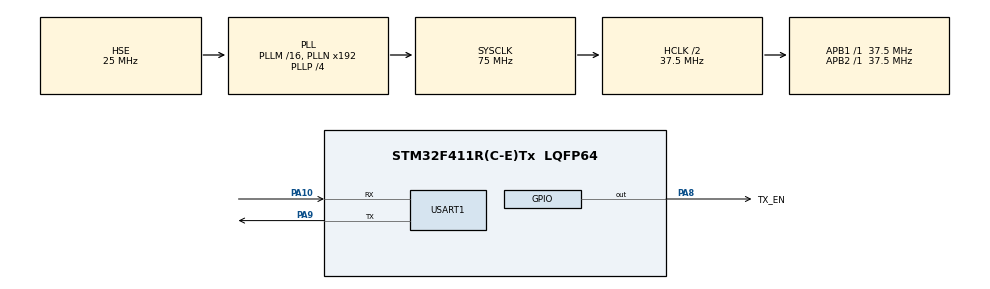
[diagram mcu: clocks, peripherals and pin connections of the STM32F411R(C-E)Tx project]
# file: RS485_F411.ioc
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Mcu.Family=STM32F4
Mcu.Name=STM32F411R(C-E)Tx
Mcu.Package=LQFP64
NVIC.PriorityGroup=NVIC_PRIORITYGROUP_4
NVIC.USART1_IRQn=true\:0\:0\:false\:false\:true\:true\:true\:true
PA10.Mode=Asynchronous
PA10.Signal=USART1_RX
PA13.Mode=Serial_Wire
PA13.Signal=SYS_JTMS-SWDIO
PA14.Mode=Serial_Wire
PA14.Signal=SYS_JTCK-SWCLK
PA8.GPIO_Label=TX_EN
PA8.Signal=GPIO_Output
PA9.Mode=Asynchronous
PA9.Signal=USART1_TX
PH0\ -\ OSC_IN.Mode=HSE-External-Oscillator
PH0\ -\ OSC_IN.Signal=RCC_OSC_IN
PH1\ -\ OSC_OUT.Mode=HSE-External-Oscillator
PH1\ -\ OSC_OUT.Signal=RCC_OSC_OUT
ProjectManager.HeapSize=0x200
ProjectManager.StackSize=0x400
ProjectManager.TargetToolchain=STM32CubeIDE
RCC.48MHZClocksFreq_Value=75000000
RCC.AHBCLKDivider=RCC_SYSCLK_DIV2
RCC.AHBFreq_Value=37500000
RCC.APB1Freq_Value=37500000
RCC.APB1TimFreq_Value=37500000
RCC.APB2Freq_Value=37500000
RCC.APB2TimFreq_Value=37500000
RCC.CortexFreq_Value=37500000
RCC.HCLKFreq_Value=37500000
RCC.HSE_VALUE=25000000
RCC.HSI_VALUE=16000000
RCC.LSE_VALUE=32768
RCC.PLLP=RCC_PLLP_DIV4
RCC.PLLSourceVirtual=RCC_PLLSOURCE_HSE
RCC.SYSCLKFreq_VALUE=75000000
RCC.SYSCLKSource=RCC_SYSCLKSOURCE_PLLCLK
RCC.VCOOutputFreq_Value=300000000
USART1.VirtualMode=VM_ASYNC
board=custom

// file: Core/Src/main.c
/* USER CODE BEGIN Header */
/**
  ******************************************************************************
  * @file           : main.c
  * @brief          : Main program body
  ******************************************************************************
  * @attention
  *
  * Copyright (c) 2022 STMicroelectronics.
  * All rights reserved.
  *
  * This software is licensed under terms that can be found in the LICENSE file
  * in the root directory of this software component.
  * If no LICENSE file comes with this software, it is provided AS-IS.
  *
  ******************************************************************************
  */
/* USER CODE END Header */
#include "main.h"

/* USER CODE BEGIN Includes */
#include"stdio.h"
#include"string.h"
/* USER CODE END Includes */

UART_HandleTypeDef huart1;

void SystemClock_Config(void);
static void MX_GPIO_Init(void);
static void MX_USART1_UART_Init(void);

/* USER CODE BEGIN 0 */
uint8_t TxData[16];
uint8_t RxData[16];
int indx = 0;

void sendData(uint8_t *data)
{
	HAL_GPIO_WritePin(TX_EN_GPIO_Port,TX_EN_Pin,GPIO_PIN_SET); //PULL DE high to enable Tx operation
	HAL_UART_Transmit(&huart1, data, strlen(data), 1000);
	HAL_GPIO_WritePin(TX_EN_GPIO_Port,TX_EN_Pin,GPIO_PIN_RESET);//PULL RE high to enable Rx operation
}

void HAL_UARTEx_RxEventCallback(UART_HandleTypeDef *huart, uint16_t Size)
{
	RxData[0] = 'F';
	RxData[1] = '4';
	RxData[2] = '4';
	RxData[3] = '6';
	sendData(RxData);
	HAL_UARTEx_ReceiveToIdle_IT(&huart1, RxData, 64);
//	memset (RxData, '\0',64);
}
/* USER CODE END 0 */

int main(void)
{

  /* MCU Configuration--------------------------------------------------------*/

  /* Reset of all peripherals, Initializes the Flash interface and the Systick. */
  HAL_Init();

  /* Configure the system clock */
  SystemClock_Config();

  /* Initialize all configured peripherals */
  MX_GPIO_Init();
  MX_USART1_UART_Init();
  /* USER CODE BEGIN 2 */
  HAL_UARTEx_ReceiveToIdle_IT(&huart1,RxData,16);
  /* USER CODE END 2 */

  /* Infinite loop */
  while (1)
  {
	  sprintf(TxData,"F103 %d",indx++);
	  sendData(TxData);//send data to uart
	  HAL_Delay(1000);
  }
}

void SystemClock_Config(void)
{
  RCC_OscInitTypeDef RCC_OscInitStruct = {0};
  RCC_ClkInitTypeDef RCC_ClkInitStruct = {0};

  /** Configure the main internal regulator output voltage
  */
  __HAL_RCC_PWR_CLK_ENABLE();
  __HAL_PWR_VOLTAGESCALING_CONFIG(PWR_REGULATOR_VOLTAGE_SCALE1);

  /** Initializes the RCC Oscillators according to the specified parameters
  * in the RCC_OscInitTypeDef structure.
  */
  RCC_OscInitStruct.OscillatorType = RCC_OSCILLATORTYPE_HSE;
  RCC_OscInitStruct.HSEState = RCC_HSE_ON;
  RCC_OscInitStruct.PLL.PLLState = RCC_PLL_ON;
  RCC_OscInitStruct.PLL.PLLSource = RCC_PLLSOURCE_HSE;
  RCC_OscInitStruct.PLL.PLLM = 16;
  RCC_OscInitStruct.PLL.PLLN = 192;
  RCC_OscInitStruct.PLL.PLLP = RCC_PLLP_DIV4;
  RCC_OscInitStruct.PLL.PLLQ = 4;
  if (HAL_RCC_OscConfig(&RCC_OscInitStruct) != HAL_OK)
  {
    Error_Handler();
  }

  /** Initializes the CPU, AHB and APB buses clocks
  */
  RCC_ClkInitStruct.ClockType = RCC_CLOCKTYPE_HCLK|RCC_CLOCKTYPE_SYSCLK
                              |RCC_CLOCKTYPE_PCLK1|RCC_CLOCKTYPE_PCLK2;
  RCC_ClkInitStruct.SYSCLKSource = RCC_SYSCLKSOURCE_PLLCLK;
  RCC_ClkInitStruct.AHBCLKDivider = RCC_SYSCLK_DIV2;
  RCC_ClkInitStruct.APB1CLKDivider = RCC_HCLK_DIV1;
  RCC_ClkInitStruct.APB2CLKDivider = RCC_HCLK_DIV1;

  if (HAL_RCC_ClockConfig(&RCC_ClkInitStruct, FLASH_LATENCY_1) != HAL_OK)
  {
    Error_Handler();
  }
}

static void MX_USART1_UART_Init(void)
{

  huart1.Instance = USART1;
  huart1.Init.BaudRate = 115200;
  huart1.Init.WordLength = UART_WORDLENGTH_8B;
  huart1.Init.StopBits = UART_STOPBITS_1;
  huart1.Init.Parity = UART_PARITY_NONE;
  huart1.Init.Mode = UART_MODE_TX_RX;
  huart1.Init.HwFlowCtl = UART_HWCONTROL_NONE;
  huart1.Init.OverSampling = UART_OVERSAMPLING_16;
  if (HAL_UART_Init(&huart1) != HAL_OK)
  {
    Error_Handler();
  }

}

static void MX_GPIO_Init(void)
{
  GPIO_InitTypeDef GPIO_InitStruct = {0};

  /* GPIO Ports Clock Enable */
  __HAL_RCC_GPIOH_CLK_ENABLE();
  __HAL_RCC_GPIOA_CLK_ENABLE();

  /*Configure GPIO pin Output Level */
  HAL_GPIO_WritePin(TX_EN_GPIO_Port, TX_EN_Pin, GPIO_PIN_RESET);

  /*Configure GPIO pin : TX_EN_Pin */
  GPIO_InitStruct.Pin = TX_EN_Pin;
  GPIO_InitStruct.Mode = GPIO_MODE_OUTPUT_PP;
  GPIO_InitStruct.Pull = GPIO_NOPULL;
  GPIO_InitStruct.Speed = GPIO_SPEED_FREQ_LOW;
  HAL_GPIO_Init(TX_EN_GPIO_Port, &GPIO_InitStruct);

}

void Error_Handler(void)
{
  __disable_irq();
  while (1)
  {
  }
}
